# CY8C5888LTI_LP097 register map
File version: 0.1
Registers are 8-bit, read-write, no defined reset value unless marked. A register's access mark holds for its fields unless they carry their own. Offsets are from the block's base; [hi:lo] are bit positions; 'fields as' and 'values as' point back to an identical list.

## M2QuadDec
Base 0x00000000
0x40006409 M2QuadDec_Cnt16_COUNTER 16-bit — Counter value
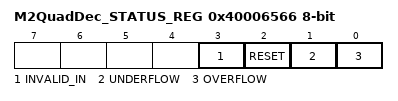
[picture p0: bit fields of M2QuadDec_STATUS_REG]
0x40006566 M2QuadDec_STATUS_REG — Quadrature Decoder Status Register
  [3] INVALID_IN ro — Invalid state transition on the A and B inputs
  [2] RESET ro — Counter Reset due index
  [1] UNDERFLOW ro — Counter underflow
  [0] OVERFLOW ro — Counter overflow

## M2QuadDec_Cnt16
Base 0x00000000
0x40006409 M2QuadDec_Cnt16_COUNTER 16-bit — UDB.A0 - Current Counter Value
0x40006429 M2QuadDec_Cnt16_PERIOD 16-bit — UDB.D0 - Assigned Period
0x40006439 M2QuadDec_Cnt16_COMPARE 16-bit — UDB.D1 - Assigned Compare Value
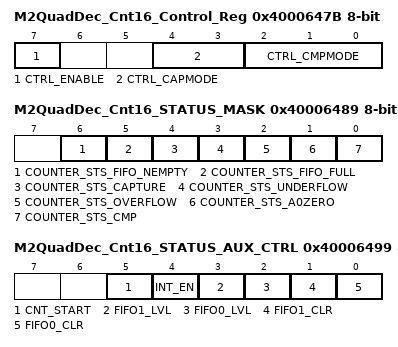
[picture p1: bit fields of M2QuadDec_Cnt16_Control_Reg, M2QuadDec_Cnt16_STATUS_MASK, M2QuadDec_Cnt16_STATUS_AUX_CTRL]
0x4000647B M2QuadDec_Cnt16_Control_Reg — UDB Control Register - Assigned Control Register Value
  [7] CTRL_ENABLE — Enable Counter
  [4:3] CTRL_CAPMODE — Capture mode
  [2:0] CTRL_CMPMODE — Compare mode
0x40006489 M2QuadDec_Cnt16_STATUS_MASK — UDB Status bits Interrupt Mask Enable Register
  [6] COUNTER_STS_FIFO_NEMPTY — FIFO Not Empty Status
  [5] COUNTER_STS_FIFO_FULL — FIFO Full Status
  [4] COUNTER_STS_CAPTURE — Capture Status
  [3] COUNTER_STS_UNDERFLOW — Underflow status
  [2] COUNTER_STS_OVERFLOW — Overflow status
  [1] COUNTER_STS_A0ZERO — A0 Zero ouput status
  [0] COUNTER_STS_CMP — Compare output status
0x40006499 M2QuadDec_Cnt16_STATUS_AUX_CTRL — UDB Auxilliary Control Register
  [5] CNT_START — FIFO0 clear
    0=E_CNT_START0 (Disable counter); 1=E_CNT_START1 (Enable counter)
  [4] INT_EN
    0=E_INT_EN0 (Interrupt disabled); 1=E_INT_EN1 (Interrupt enabled)
  [3] FIFO1_LVL — FIFO level
    0=E_FIFO_LVL_0 (FIFO LVL: input mode: FIFO not full; output mode: FIFO not empty); 1=E_FIFO_LVL_1 (FIFO LVL: input mode: FIFO at least 1/2 empty; output mode: FIFO at least 1/2 full)
  [2] FIFO0_LVL — FIFO level
    values as FIFO1_LVL
  [1] FIFO1_CLR — FIFO1 clear
    0=E_FIFO_CLR_0 (Normal FIFO operation); 1=E_FIFO_CLR_1 (Clear FIFO state)
  [0] FIFO0_CLR — FIFO0 clear
    values as FIFO1_CLR

## PWM_2
Base 0x00000000
0x40006524 PWM_2_COMPARE_Reg 16-bit — UDB.D0 - Assigned Compare Value
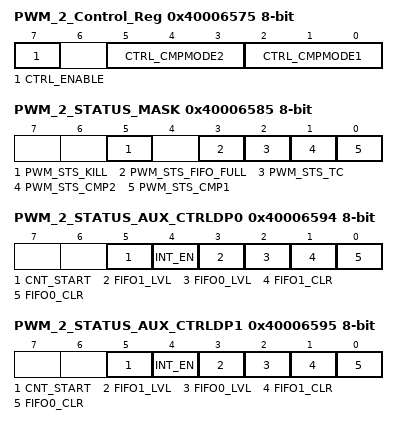
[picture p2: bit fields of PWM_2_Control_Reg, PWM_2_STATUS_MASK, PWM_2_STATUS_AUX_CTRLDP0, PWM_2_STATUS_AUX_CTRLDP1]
0x40006575 PWM_2_Control_Reg — UDB Control Register - Assigned Control Register Value
  [7] CTRL_ENABLE — Enable the PWM
  [5:3] CTRL_CMPMODE2 — Compare mode 2
  [2:0] CTRL_CMPMODE1 — Compare mode 1
0x40006585 PWM_2_STATUS_MASK — UDB Status bits Interrupt Mask Enable Register
  [5] PWM_STS_KILL ro — Enables the Interrupt on Kill
  [3] PWM_STS_FIFO_FULL ro — FIFO Full Status Mask
  [2] PWM_STS_TC ro — Enables the Interrupt on Terminal Count
  [1] PWM_STS_CMP2 ro — Enables the Interrupt on Compare 2
  [0] PWM_STS_CMP1 ro — Enables the Interrupt on Compare 1
0x40006594 PWM_2_STATUS_AUX_CTRLDP0 — UDB Auxilliary Control Register
  [5] CNT_START — FIFO0 clear
    0=E_CNT_START0 (Disable counter); 1=E_CNT_START1 (Enable counter)
  [4] INT_EN
    0=E_INT_EN0 (Interrupt disabled); 1=E_INT_EN1 (Interrupt enabled)
  [3] FIFO1_LVL — FIFO level
    0=E_FIFO_LVL_0 (FIFO LVL: input mode: FIFO not full; output mode: FIFO not empty); 1=E_FIFO_LVL_1 (FIFO LVL: input mode: FIFO at least 1/2 empty; output mode: FIFO at least 1/2 full)
  [2] FIFO0_LVL — FIFO level
    values as FIFO1_LVL
  [1] FIFO1_CLR — FIFO1 clear
    0=E_FIFO_CLR_0 (Normal FIFO operation); 1=E_FIFO_CLR_1 (Clear FIFO state)
  [0] FIFO0_CLR — FIFO0 clear
    values as FIFO1_CLR
0x40006595 PWM_2_STATUS_AUX_CTRLDP1 — UDB Auxilliary Control Register
  fields as PWM_2_STATUS_AUX_CTRLDP0

## PWM_1
Base 0x00000000
0x40006426 PWM_1_COMPARE_Reg 16-bit — UDB.D0 - Assigned Compare Value
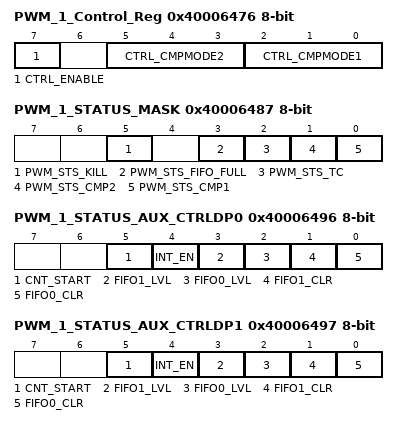
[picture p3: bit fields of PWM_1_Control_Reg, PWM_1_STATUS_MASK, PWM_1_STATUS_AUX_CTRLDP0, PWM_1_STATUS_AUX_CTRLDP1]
0x40006476 PWM_1_Control_Reg — UDB Control Register - Assigned Control Register Value
  [7] CTRL_ENABLE — Enable the PWM
  [5:3] CTRL_CMPMODE2 — Compare mode 2
  [2:0] CTRL_CMPMODE1 — Compare mode 1
0x40006487 PWM_1_STATUS_MASK — UDB Status bits Interrupt Mask Enable Register
  [5] PWM_STS_KILL ro — Enables the Interrupt on Kill
  [3] PWM_STS_FIFO_FULL ro — FIFO Full Status Mask
  [2] PWM_STS_TC ro — Enables the Interrupt on Terminal Count
  [1] PWM_STS_CMP2 ro — Enables the Interrupt on Compare 2
  [0] PWM_STS_CMP1 ro — Enables the Interrupt on Compare 1
0x40006496 PWM_1_STATUS_AUX_CTRLDP0 — UDB Auxilliary Control Register
  [5] CNT_START — FIFO0 clear
    0=E_CNT_START0 (Disable counter); 1=E_CNT_START1 (Enable counter)
  [4] INT_EN
    0=E_INT_EN0 (Interrupt disabled); 1=E_INT_EN1 (Interrupt enabled)
  [3] FIFO1_LVL — FIFO level
    0=E_FIFO_LVL_0 (FIFO LVL: input mode: FIFO not full; output mode: FIFO not empty); 1=E_FIFO_LVL_1 (FIFO LVL: input mode: FIFO at least 1/2 empty; output mode: FIFO at least 1/2 full)
  [2] FIFO0_LVL — FIFO level
    values as FIFO1_LVL
  [1] FIFO1_CLR — FIFO1 clear
    0=E_FIFO_CLR_0 (Normal FIFO operation); 1=E_FIFO_CLR_1 (Clear FIFO state)
  [0] FIFO0_CLR — FIFO0 clear
    values as FIFO1_CLR
0x40006497 PWM_1_STATUS_AUX_CTRLDP1 — UDB Auxilliary Control Register
  fields as PWM_1_STATUS_AUX_CTRLDP0

## PWM_M1
Base 0x00000000
0x40006422 PWM_M1_COMPARE_Reg 16-bit — UDB.D0 - Assigned Compare Value
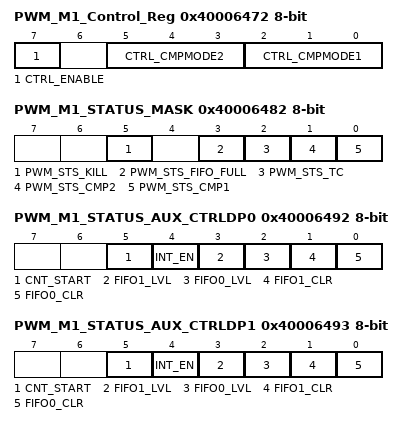
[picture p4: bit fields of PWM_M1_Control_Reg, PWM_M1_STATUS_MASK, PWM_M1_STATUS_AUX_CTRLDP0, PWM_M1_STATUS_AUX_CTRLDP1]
0x40006472 PWM_M1_Control_Reg — UDB Control Register - Assigned Control Register Value
  [7] CTRL_ENABLE — Enable the PWM
  [5:3] CTRL_CMPMODE2 — Compare mode 2
  [2:0] CTRL_CMPMODE1 — Compare mode 1
0x40006482 PWM_M1_STATUS_MASK — UDB Status bits Interrupt Mask Enable Register
  [5] PWM_STS_KILL ro — Enables the Interrupt on Kill
  [3] PWM_STS_FIFO_FULL ro — FIFO Full Status Mask
  [2] PWM_STS_TC ro — Enables the Interrupt on Terminal Count
  [1] PWM_STS_CMP2 ro — Enables the Interrupt on Compare 2
  [0] PWM_STS_CMP1 ro — Enables the Interrupt on Compare 1
0x40006492 PWM_M1_STATUS_AUX_CTRLDP0 — UDB Auxilliary Control Register
  [5] CNT_START — FIFO0 clear
    0=E_CNT_START0 (Disable counter); 1=E_CNT_START1 (Enable counter)
  [4] INT_EN
    0=E_INT_EN0 (Interrupt disabled); 1=E_INT_EN1 (Interrupt enabled)
  [3] FIFO1_LVL — FIFO level
    0=E_FIFO_LVL_0 (FIFO LVL: input mode: FIFO not full; output mode: FIFO not empty); 1=E_FIFO_LVL_1 (FIFO LVL: input mode: FIFO at least 1/2 empty; output mode: FIFO at least 1/2 full)
  [2] FIFO0_LVL — FIFO level
    values as FIFO1_LVL
  [1] FIFO1_CLR — FIFO1 clear
    0=E_FIFO_CLR_0 (Normal FIFO operation); 1=E_FIFO_CLR_1 (Clear FIFO state)
  [0] FIFO0_CLR — FIFO0 clear
    values as FIFO1_CLR
0x40006493 PWM_M1_STATUS_AUX_CTRLDP1 — UDB Auxilliary Control Register
  fields as PWM_M1_STATUS_AUX_CTRLDP0

## UART_1 — UART
Base 0x00000000
0x40006420 RX_UART_1_RX_ADDRESS1 — RX Address1 Register
0x40006430 RX_UART_1_RX_ADDRESS2 — RX Address2 Register
0x40006440 RX_UART_1_RX_DATA — RX Data Register
0x40006448 TX_UART_1_TX_DATA — TX Data Register
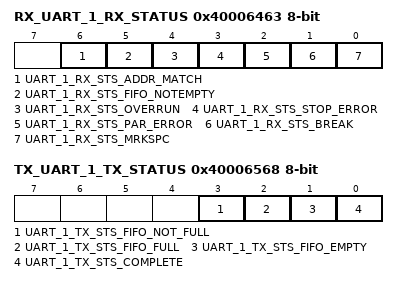
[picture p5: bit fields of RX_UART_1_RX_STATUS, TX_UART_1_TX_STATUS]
0x40006463 RX_UART_1_RX_STATUS — RX status register
  [6] UART_1_RX_STS_ADDR_MATCH ro, [5] UART_1_RX_STS_FIFO_NOTEMPTY ro, [4] UART_1_RX_STS_OVERRUN ro, [3] UART_1_RX_STS_STOP_ERROR ro, [2] UART_1_RX_STS_PAR_ERROR ro, [1] UART_1_RX_STS_BREAK ro, [0] UART_1_RX_STS_MRKSPC ro
0x40006568 TX_UART_1_TX_STATUS — TX status register
  [3] UART_1_TX_STS_FIFO_NOT_FULL ro, [2] UART_1_TX_STS_FIFO_FULL ro, [1] UART_1_TX_STS_FIFO_EMPTY ro, [0] UART_1_TX_STS_COMPLETE ro

## PWM_M2
Base 0x00000000
0x40006424 PWM_M2_COMPARE_Reg 16-bit — UDB.D0 - Assigned Compare Value
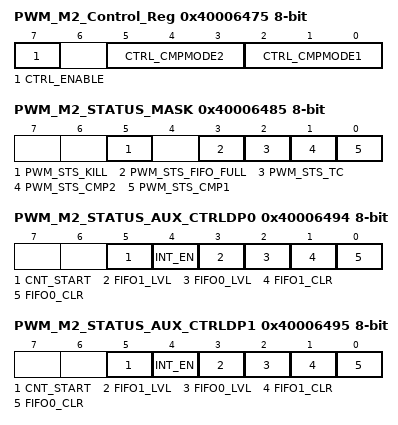
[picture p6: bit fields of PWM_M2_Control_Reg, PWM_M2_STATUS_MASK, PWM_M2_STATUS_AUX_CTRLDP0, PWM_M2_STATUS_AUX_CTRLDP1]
0x40006475 PWM_M2_Control_Reg — UDB Control Register - Assigned Control Register Value
  [7] CTRL_ENABLE — Enable the PWM
  [5:3] CTRL_CMPMODE2 — Compare mode 2
  [2:0] CTRL_CMPMODE1 — Compare mode 1
0x40006485 PWM_M2_STATUS_MASK — UDB Status bits Interrupt Mask Enable Register
  [5] PWM_STS_KILL ro — Enables the Interrupt on Kill
  [3] PWM_STS_FIFO_FULL ro — FIFO Full Status Mask
  [2] PWM_STS_TC ro — Enables the Interrupt on Terminal Count
  [1] PWM_STS_CMP2 ro — Enables the Interrupt on Compare 2
  [0] PWM_STS_CMP1 ro — Enables the Interrupt on Compare 1
0x40006494 PWM_M2_STATUS_AUX_CTRLDP0 — UDB Auxilliary Control Register
  [5] CNT_START — FIFO0 clear
    0=E_CNT_START0 (Disable counter); 1=E_CNT_START1 (Enable counter)
  [4] INT_EN
    0=E_INT_EN0 (Interrupt disabled); 1=E_INT_EN1 (Interrupt enabled)
  [3] FIFO1_LVL — FIFO level
    0=E_FIFO_LVL_0 (FIFO LVL: input mode: FIFO not full; output mode: FIFO not empty); 1=E_FIFO_LVL_1 (FIFO LVL: input mode: FIFO at least 1/2 empty; output mode: FIFO at least 1/2 full)
  [2] FIFO0_LVL — FIFO level
    values as FIFO1_LVL
  [1] FIFO1_CLR — FIFO1 clear
    0=E_FIFO_CLR_0 (Normal FIFO operation); 1=E_FIFO_CLR_1 (Clear FIFO state)
  [0] FIFO0_CLR — FIFO0 clear
    values as FIFO1_CLR
0x40006495 PWM_M2_STATUS_AUX_CTRLDP1 — UDB Auxilliary Control Register
  fields as PWM_M2_STATUS_AUX_CTRLDP0
